VERSION ""

NS_ :

BS_:

BU_: IAP ODS _4WD BCM HUD DATC MDPS AAF_Tester AEMC SMK _4WD EPB CUBIS MTS TMU EVP CGW TPMS LPI DI_BOX SPAS EMS LCA TCU IBOX FATC AFLS FPCM SCC AHLS AVM ABS SNV OPI PGS SAS AAF Dummy LDWS_LKAS LVR ESC PSB CLU ECS ACU REA

BO_ 67 DATC13: 8 DATC
 SG_ CF_Datc_TempDispUnit : 0|2@1+ (1,0) [0|3] "" CLU,IBOX
 SG_ CF_Datc_ModDisp : 2|4@1+ (1,0) [0|15] "" CLU
 SG_ CF_Datc_IonClean : 6|2@1+ (1,0) [0|3] "" CLU
 SG_ CF_Datc_ChgReqDisp : 8|2@1+ (1,0) [0|3] "" CLU
 SG_ CF_Datc_IntakeDisp : 10|2@1+ (1,0) [0|3] "" CLU
 SG_ CF_Datc_AutoDisp : 12|2@1+ (1,0) [0|3] "" CLU
 SG_ CF_Datc_FrDefLed : 14|2@1+ (1,0) [0|3] "" CLU,IBOX
 SG_ CF_Datc_AutoDefogBlink : 16|2@1+ (1,0) [0|3] "" CLU
 SG_ CF_Datc_ClmScanDisp : 18|2@1+ (1,0) [0|3] "" CLU
 SG_ CF_Datc_AqsDisp : 20|2@1+ (1,0) [0|3] "" CLU
 SG_ CF_Datc_AcDisp : 22|2@1+ (1,0) [0|3] "" CLU
 SG_ CF_Datc_OpSts : 25|3@1+ (1,0) [0|7] "" CLU
 SG_ CF_Mtc_MaxAcDisp : 28|2@1+ (1,0) [0|3] "" CLU
 SG_ CF_Datc_DualDisp : 30|2@1+ (1,0) [0|3] "" CLU
 SG_ CF_Datc_PwrInf : 32|4@1+ (1,0) [0|15] "" CLU
 SG_ CF_Datc_RearManual : 38|2@1+ (1,0) [0|3] "" CLU
 SG_ CF_Datc_RearAutoDisp : 40|2@1+ (1,0) [0|1] "" CLU
 SG_ CF_Datc_RearOffDisp : 42|2@1+ (1,0) [0|3] "" CLU
 SG_ CF_Datc_RearClimateScnDisp : 44|2@1+ (1,0) [0|3] "" CLU
 SG_ CF_Datc_RearChgReqDisp : 46|2@1+ (1,0) [0|3] "" CLU
 SG_ CF_Datc_RearModDisp : 48|4@1+ (1,0) [0|15] "" CLU
 SG_ CF_Datc_RearBlwDisp : 52|4@1+ (1,0) [0|15] "" CLU
 SG_ CF_Datc_PSModDisp : 56|4@1+ (1,0) [0|15] "" CLU
 SG_ CF_Datc_FrontBlwDisp : 60|4@1+ (1,0) [0|15] "" CLU,IBOX

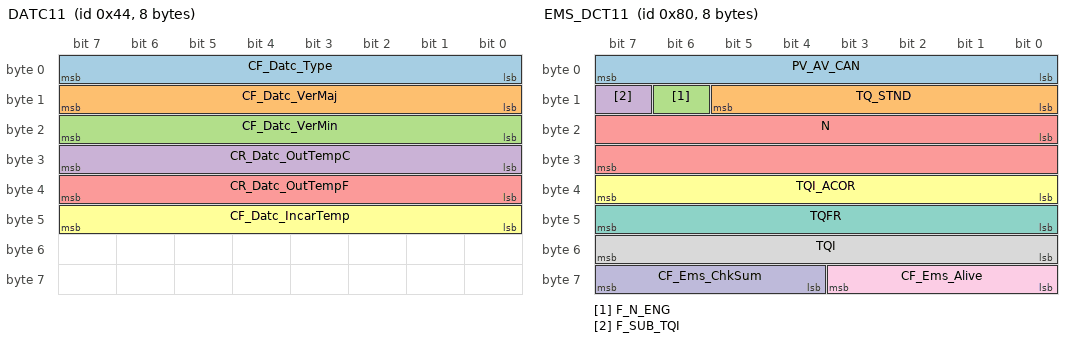
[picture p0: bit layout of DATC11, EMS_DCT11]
BO_ 68 DATC11: 8 DATC
 SG_ CF_Datc_Type : 0|8@1+ (1,0) [0|255] "" CLU
 SG_ CF_Datc_VerMaj : 8|8@1+ (1,0) [0|255] "" CLU
 SG_ CF_Datc_VerMin : 16|8@1+ (1,0) [0|255] "" CLU
 SG_ CR_Datc_OutTempC : 24|8@1+ (0.5,-41) [-41|86.5] "deg" CLU,FPCM
 SG_ CR_Datc_OutTempF : 32|8@1+ (1,-42) [-42|213] "deg" CLU
 SG_ CF_Datc_IncarTemp : 40|8@1+ (0.5,-40) [-40|60] "deg" BCM,CLU

BO_ 128 EMS_DCT11: 8 EMS
 SG_ PV_AV_CAN : 0|8@1+ (0.3906,0) [0|99.603] "%" TCU
 SG_ TQ_STND : 8|6@1+ (10,0) [0|630] "Nm" TCU
 SG_ F_N_ENG : 14|1@1+ (1,0) [0|1] "" TCU
 SG_ F_SUB_TQI : 15|1@1+ (1,0) [0|1] "" TCU
 SG_ N : 16|16@1+ (0.25,0) [0|16383.75] "rpm" TCU
 SG_ TQI_ACOR : 32|8@1+ (0.390625,0) [0|99.6094] "%" IBOX,TCU
 SG_ TQFR : 40|8@1+ (0.390625,0) [0|99.6094] "%" TCU
 SG_ TQI : 48|8@1+ (0.390625,0) [0|99.609375] "%" TCU
 SG_ CF_Ems_Alive : 56|4@1+ (1,0) [0|15] "" TCU
 SG_ CF_Ems_ChkSum : 60|4@1+ (1,0) [0|15] "" TCU

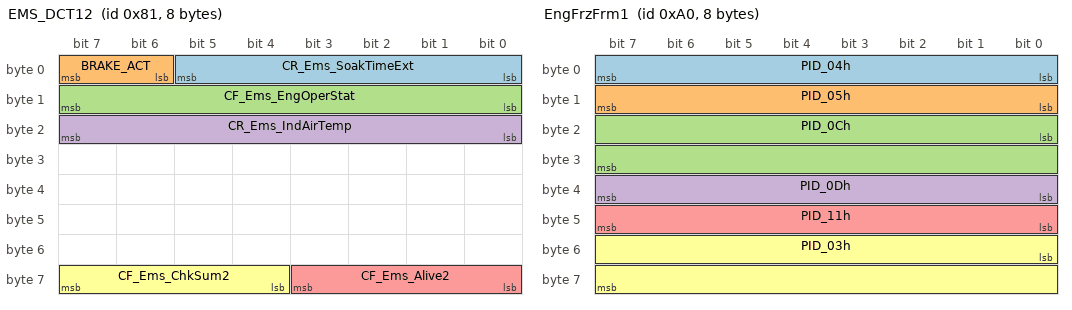
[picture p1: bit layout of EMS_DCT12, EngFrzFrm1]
BO_ 129 EMS_DCT12: 8 EMS
 SG_ CR_Ems_SoakTimeExt : 0|6@1+ (5,0) [0|315] "Min" TCU
 SG_ BRAKE_ACT : 6|2@1+ (1,0) [0|3] "" TCU
 SG_ CF_Ems_EngOperStat : 8|8@1+ (1,0) [0|255] "" TCU
 SG_ CR_Ems_IndAirTemp : 16|8@1+ (0.75,-48) [-48|143.25] "deg" TCU
 SG_ CF_Ems_Alive2 : 56|4@1+ (1,0) [0|15] "" TCU
 SG_ CF_Ems_ChkSum2 : 60|4@1+ (1,0) [0|15] "" TCU

BO_ 160 EngFrzFrm1: 8 XXX
 SG_ PID_04h : 0|8@1+ (0.392157,0) [0|100] "%" XXX
 SG_ PID_05h : 8|8@1+ (1,-40) [-40|215] "" XXX
 SG_ PID_0Ch : 16|16@1+ (0.25,0) [0|16383.8] "rpm" XXX
 SG_ PID_0Dh : 32|8@1+ (1,0) [0|255] "km/h" XXX
 SG_ PID_11h : 40|8@1+ (0.392157,0) [0|100] "%" XXX
 SG_ PID_03h : 48|16@1+ (1,0) [0|65535] "" XXX

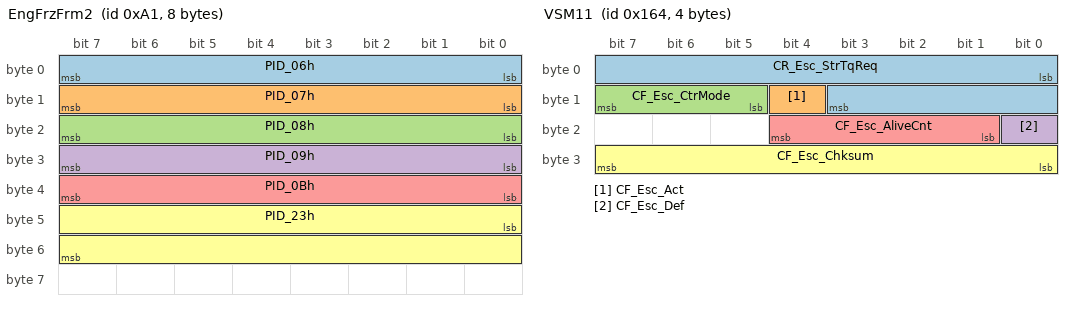
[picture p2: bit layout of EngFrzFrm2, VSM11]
BO_ 161 EngFrzFrm2: 8 XXX
 SG_ PID_06h : 0|8@1+ (0.78125,-100) [-100|99.22] "%" XXX
 SG_ PID_07h : 8|8@1+ (0.78125,-100) [-100|99.22] "%" XXX
 SG_ PID_08h : 16|8@1+ (0.78125,-100) [-100|99.22] "%" XXX
 SG_ PID_09h : 24|8@1+ (0.78125,-100) [-100|99.22] "%" XXX
 SG_ PID_0Bh : 32|8@1+ (1,0) [0|255] "kPa" XXX
 SG_ PID_23h : 40|16@1+ (10,0) [0|655350] "kPa" XXX

BO_ 339 TCS11: 8 ESC
 SG_ TCS_REQ : 0|1@1+ (1,0) [0|1] "" _4WD,EMS,EPB,TCU
 SG_ MSR_C_REQ : 1|1@1+ (1,0) [0|1] "" EMS,EPB,SCC,TCU
 SG_ TCS_PAS : 2|1@1+ (1,0) [0|1] "" _4WD,CLU,EMS,SCC,SPAS,TCU
 SG_ TCS_GSC : 3|1@1+ (1,0) [0|1] "" _4WD,EMS,TCU
 SG_ CF_Esc_LimoInfo : 4|2@1+ (1,0) [0|3] "" _4WD,SCC
 SG_ ABS_DIAG : 6|1@1+ (1,0) [0|1] "" _4WD,CLU,EMS,EPB
 SG_ ABS_DEF : 7|1@1+ (1,0) [0|1] "" _4WD,ACU,ECS,EMS,EPB,SCC,SPAS,TCU
 SG_ TCS_DEF : 8|1@1+ (1,0) [0|1] "" _4WD,EMS,EPB,SCC,SPAS,TCU
 SG_ TCS_CTL : 9|1@1+ (1,0) [0|1] "" _4WD,EMS,EPB,SCC,SPAS,TCU
 SG_ ABS_ACT : 10|1@1+ (1,0) [0|1] "" _4WD,ACU,ECS,EMS,EPB,LDWS_LKAS,SCC,SPAS,TCU
 SG_ EBD_DEF : 11|1@1+ (1,0) [0|1] "" _4WD,EMS,EPB,SPAS,TCU
 SG_ ESP_PAS : 12|1@1+ (1,0) [0|1] "" _4WD,ACU,CLU,EMS,EPB,LDWS_LKAS,SCC,TCU
 SG_ ESP_DEF : 13|1@1+ (1,0) [0|1] "" _4WD,ACU,ECS,EMS,EPB,LDWS_LKAS,SCC,TCU
 SG_ ESP_CTL : 14|1@1+ (1,0) [0|1] "" _4WD,ACU,ECS,EMS,EPB,LDWS_LKAS,SCC,SPAS,TCU
 SG_ TCS_MFRN : 15|1@1+ (1,0) [0|1] "" EMS,EPB,TCU
 SG_ DBC_CTL : 16|1@1+ (1,0) [0|1] "" _4WD,EMS,EPB
 SG_ DBC_PAS : 17|1@1+ (1,0) [0|1] "" _4WD,EMS,EPB
 SG_ DBC_DEF : 18|1@1+ (1,0) [0|1] "" _4WD,EMS,EPB
 SG_ HAC_CTL : 19|1@1+ (1,0) [0|1] "" _4WD,CLU,EMS,EPB,TCU
 SG_ HAC_PAS : 20|1@1+ (1,0) [0|1] "" _4WD,CLU,EMS,EPB,TCU
 SG_ HAC_DEF : 21|1@1+ (1,0) [0|1] "" _4WD,CLU,EMS,EPB,TCU
 SG_ ESS_STAT : 22|2@1+ (1,0) [0|3] "" _4WD,BCM,CLU,EMS,EPB
 SG_ TQI_TCS : 24|8@1+ (0.390625,0) [0|99.609375] "%" EMS,EPB,TCU
 SG_ TQI_MSR : 32|8@1+ (0.390625,0) [0|99.609375] "%" EMS,EPB,TCU
 SG_ TQI_SLW_TCS : 40|8@1+ (0.390625,0) [0|99.609375] "%" EMS,EPB,TCU
 SG_ CF_Esc_BrkCtl : 48|1@1+ (1,0) [0|1] "" EMS
 SG_ BLA_CTL : 49|2@1+ (1,0) [0|3] "" BCM,CGW,CLU
 SG_ AliveCounter_TCS1 : 52|4@1+ (1,0) [0|14] "" EMS,EPB,LDWS_LKAS
 SG_ CheckSum_TCS1 : 56|8@1+ (1,0) [0|255] "" EMS,EPB,LDWS_LKAS

BO_ 356 VSM11: 4 ESC
 SG_ CR_Esc_StrTqReq : 0|12@1+ (0.01,-20.48) [-20.48|20.47] "Nm" MDPS
 SG_ CF_Esc_Act : 12|1@1+ (1,0) [0|1] "" LDWS_LKAS,MDPS
 SG_ CF_Esc_CtrMode : 13|3@1+ (1,0) [0|7] "" MDPS
 SG_ CF_Esc_Def : 16|1@1+ (1,0) [0|1] "" MDPS
 SG_ CF_Esc_AliveCnt : 17|4@1+ (1,0) [0|15] "" LDWS_LKAS,MDPS
 SG_ CF_Esc_Chksum : 24|8@1+ (1,0) [0|255] "" LDWS_LKAS,MDPS

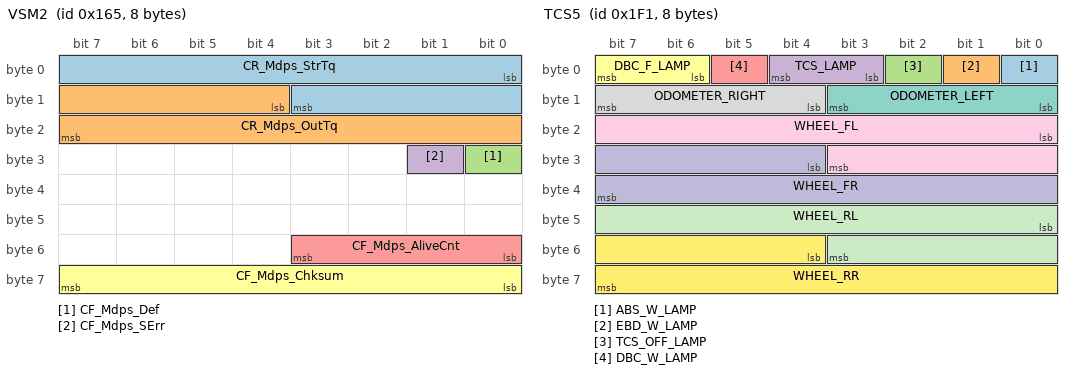
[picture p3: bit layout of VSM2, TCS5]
BO_ 357 VSM2: 8 XXX
 SG_ CR_Mdps_StrTq : 0|12@1+ (0.01,-20.48) [-20.48|20.47] "Nm" XXX
 SG_ CR_Mdps_OutTq : 12|12@1+ (0.1,-204.8) [-204.8|204.7] "" XXX
 SG_ CF_Mdps_Def : 24|1@1+ (1,0) [0|1] "" XXX
 SG_ CF_Mdps_SErr : 25|1@1+ (1,0) [0|1] "" XXX
 SG_ CF_Mdps_AliveCnt : 48|4@1+ (1,0) [0|15] "" XXX
 SG_ CF_Mdps_Chksum : 56|8@1+ (1,0) [0|255] "" XXX

BO_ 399 EMS_H12: 8 EMS
 SG_ R_TqAcnApvC : 0|8@1+ (0.2,0) [0|51] "Nm" DATC,IBOX
 SG_ R_PAcnC : 8|8@1+ (125,0) [0|31875] "hPa" DATC,IBOX
 SG_ TQI_B : 16|8@1+ (0.390625,0) [0|99.609375] "%" ABS,ESC,IBOX
 SG_ SLD_VS : 24|8@1+ (1,0) [0|255] "km/h" CLU,IBOX
 SG_ CF_CdaStat : 32|3@1+ (1,0) [0|7] "" AEMC,IBOX,TCU
 SG_ CF_Ems_IsgStat : 35|3@1+ (1,0) [0|7] "" ABS,BCM,CLU,DATC,EPB,ESC,IBOX,LDWS_LKAS,MDPS,SMK,TCU
 SG_ CF_Ems_OilChg : 38|1@1+ (1,0) [0|1] "" CLU,IBOX
 SG_ CF_Ems_EtcLimpMod : 39|1@1+ (1,0) [0|1] "" CLU,IBOX
 SG_ R_NEngIdlTgC : 40|8@1+ (10,0) [0|2550] "rpm" DATC,IBOX,TCU
 SG_ CF_Ems_UpTarGr : 48|1@1+ (1,0) [0|1] "" CLU,IBOX
 SG_ CF_Ems_DownTarGr : 49|1@1+ (1,0) [0|1] "" CLU,IBOX
 SG_ CF_Ems_DesCurGr : 50|4@1+ (1,0) [0|15] "" CLU,IBOX
 SG_ CF_Ems_SldAct : 54|1@1+ (1,0) [0|1] "" CLU,IBOX
 SG_ CF_Ems_SldPosAct : 55|1@1+ (1,0) [0|1] "" CLU,IBOX
 SG_ CF_Ems_HPresStat : 56|1@1+ (1,0) [0|1] "" IBOX,TCU
 SG_ CF_Ems_IsgBuz : 57|1@1+ (1,0) [0|1] "" CLU,IBOX
 SG_ CF_Ems_IdlStpFCO : 58|1@1+ (1,0) [0|1] "" CLU,IBOX
 SG_ CF_Ems_FCopen : 59|1@1+ (1,0) [0|1] "" CLU,IBOX
 SG_ CF_Ems_ActEcoAct : 60|1@1+ (1,0) [0|1] "" CLU,IBOX,TCU
 SG_ CF_Ems_EngRunNorm : 61|1@1+ (1,0) [0|1] "" ABS,ESC,IBOX,TCU
 SG_ CF_Ems_IsgStat2 : 62|2@1+ (2,0) [0|3] "" CLU,IBOX,TCU

BO_ 497 TCS5: 8 XXX
 SG_ ABS_W_LAMP : 0|1@1+ (1,0) [0|1] "" XXX
 SG_ EBD_W_LAMP : 1|1@1+ (1,0) [0|1] "" XXX
 SG_ TCS_OFF_LAMP : 2|1@1+ (1,0) [0|1] "" XXX
 SG_ TCS_LAMP : 3|2@1+ (1,0) [0|3] "" XXX
 SG_ DBC_W_LAMP : 5|1@1+ (1,0) [0|1] "" XXX
 SG_ DBC_F_LAMP : 6|2@1+ (1,0) [0|3] "" XXX
 SG_ ODOMETER_LEFT : 8|4@1+ (1,0) [0|15] "m" XXX
 SG_ ODOMETER_RIGHT : 12|4@1+ (1,0) [0|15] "m" XXX
 SG_ WHEEL_FL : 16|12@1+ (0.125,0) [0|511.875] "km/h" XXX
 SG_ WHEEL_FR : 28|12@1+ (0.125,0) [0|511.875] "km/h" XXX
 SG_ WHEEL_RL : 40|12@1+ (0.125,0) [0|511.875] "km/h" XXX
 SG_ WHEEL_RR : 52|12@1+ (0.125,0) [0|511.875] "km/h" XXX

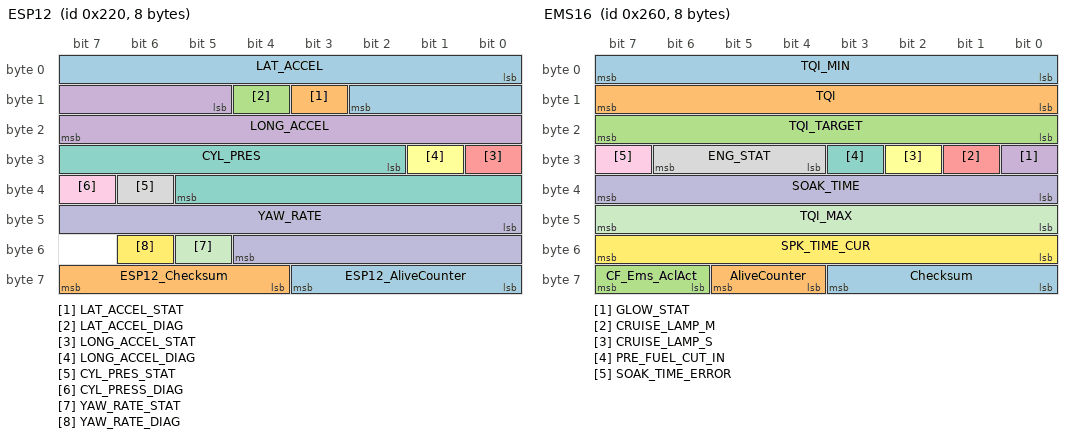
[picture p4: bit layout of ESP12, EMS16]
BO_ 544 ESP12: 8 ESC
 SG_ LAT_ACCEL : 0|11@1+ (0.01,-10.23) [-10.23|10.24] "m/s^2" _4WD,ECS,IBOX,LCA,LDWS_LKAS,MDPS,PSB,SCC,TCU
 SG_ LAT_ACCEL_STAT : 11|1@1+ (1,0) [0|1] "" _4WD,IBOX,LDWS_LKAS,MDPS,PSB,SCC,TCU
 SG_ LAT_ACCEL_DIAG : 12|1@1+ (1,0) [0|1] "" _4WD,IBOX,LDWS_LKAS,MDPS,PSB,SCC,TCU
 SG_ LONG_ACCEL : 13|11@1+ (0.01,-10.23) [-10.23|10.24] "m/s^2" _4WD,ECS,EMS,EPB,IBOX,LCA,LDWS_LKAS,PSB,SCC,SPAS,TCU
 SG_ LONG_ACCEL_STAT : 24|1@1+ (1,0) [0|1] "" _4WD,EMS,EPB,IBOX,LDWS_LKAS,PSB,SCC,SPAS,TCU
 SG_ LONG_ACCEL_DIAG : 25|1@1+ (1,0) [0|1] "" _4WD,EMS,EPB,IBOX,LDWS_LKAS,PSB,SCC,SPAS,TCU
 SG_ CYL_PRES : 26|12@1+ (0.1,0) [0|409.5] "Bar" _4WD,ECS,EMS,EPB,IBOX,LDWS_LKAS,PSB,SCC,TCU
 SG_ CYL_PRES_STAT : 38|1@1+ (1,0) [0|1] "" _4WD,ECS,EMS,EPB,IBOX,LDWS_LKAS,PSB,SCC,TCU
 SG_ CYL_PRESS_DIAG : 39|1@1+ (1,0) [0|1] "" _4WD,ECS,EMS,EPB,IBOX,PSB,SCC,TCU
 SG_ YAW_RATE : 40|13@1+ (0.01,-40.95) [-40.95|40.96] "" _4WD,AFLS,IBOX,LCA,LDWS_LKAS,MDPS,PSB,SCC,SPAS,TCU
 SG_ YAW_RATE_STAT : 53|1@1+ (1,0) [0|1] "" _4WD,AFLS,IBOX,LCA,LDWS_LKAS,MDPS,PSB,SCC,SPAS,TCU
 SG_ YAW_RATE_DIAG : 54|1@1+ (1,0) [0|1] "" _4WD,AFLS,IBOX,LCA,LDWS_LKAS,MDPS,PSB,SCC,SPAS,TCU
 SG_ ESP12_AliveCounter : 56|4@1+ (1,0) [0|15] "" _4WD,EMS,LPI,TCU,TMU
 SG_ ESP12_Checksum : 60|4@1+ (1,0) [0|15] "" _4WD,EMS,LPI,TCU,TMU

BO_ 608 EMS16: 8 EMS
 SG_ TQI_MIN : 0|8@1+ (0.390625,0) [0|99.609375] "%" ESC,IBOX,TCU
 SG_ TQI : 8|8@1+ (0.390625,0) [0|99.609375] "%" ESC,IBOX,TCU
 SG_ TQI_TARGET : 16|8@1+ (0.390625,0) [0|99.609375] "%" EPB,ESC,IBOX,TCU
 SG_ GLOW_STAT : 24|1@1+ (1,0) [0|1] "" BCM,CLU,IBOX,SMK
 SG_ CRUISE_LAMP_M : 25|1@1+ (1,0) [0|1] "" CLU,IBOX,TCU
 SG_ CRUISE_LAMP_S : 26|1@1+ (1,0) [0|1] "" CLU,IBOX,TCU
 SG_ PRE_FUEL_CUT_IN : 27|1@1+ (1,0) [0|1] "" IBOX,TCU
 SG_ ENG_STAT : 28|3@1+ (1,0) [0|7] "" ABS,AHLS,AVM,BCM,CLU,EPB,ESC,EVP,FPCM,IBOX,LCA,LDWS_LKAS,MDPS,SCC,SMK,TCU
 SG_ SOAK_TIME_ERROR : 31|1@1+ (1,0) [0|1] "" DATC,EPB,IBOX,TCU
 SG_ SOAK_TIME : 32|8@1+ (1,0) [0|255] "Min" _4WD,DATC,EPB,IBOX,TCU
 SG_ TQI_MAX : 40|8@1+ (0.390625,0) [0|99.609375] "%" ESC,IBOX,TCU
 SG_ SPK_TIME_CUR : 48|8@1+ (0.375,-35.625) [-35.625|60] "" IBOX,TCU
 SG_ Checksum : 56|4@1+ (1,0) [0|15] "" ECS,IBOX,LDWS_LKAS,MDPS,SCC
 SG_ AliveCounter : 60|2@1+ (1,0) [0|3] "" IBOX,LDWS_LKAS,MDPS,SCC
 SG_ CF_Ems_AclAct : 62|2@1+ (1,0) [0|3] "" IBOX,SCC

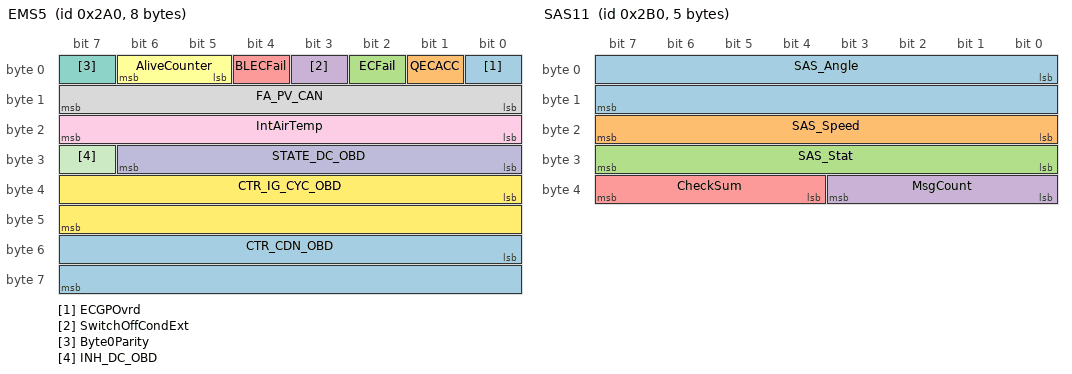
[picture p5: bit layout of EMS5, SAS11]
BO_ 672 EMS5: 8 XXX
 SG_ ECGPOvrd : 0|1@1+ (1,0) [0|1] "" XXX
 SG_ QECACC : 1|1@1+ (1,0) [0|1] "" XXX
 SG_ ECFail : 2|1@1+ (1,0) [0|1] "" XXX
 SG_ SwitchOffCondExt : 3|1@1+ (1,0) [0|1] "" XXX
 SG_ BLECFail : 4|1@1+ (1,0) [0|1] "" XXX
 SG_ AliveCounter : 5|2@1+ (1,0) [0|3] "" XXX
 SG_ Byte0Parity : 7|1@1+ (1,0) [0|1] "" XXX
 SG_ FA_PV_CAN : 8|8@1+ (0.3906,0) [0|99.2] "%" XXX
 SG_ IntAirTemp : 16|8@1+ (0.75,-48) [-48|143.25] "" XXX
 SG_ STATE_DC_OBD : 24|7@1+ (1,0) [0|127] "" XXX
 SG_ INH_DC_OBD : 31|1@1+ (1,0) [0|1] "" XXX
 SG_ CTR_IG_CYC_OBD : 32|16@1+ (1,0) [0|65535] "" XXX
 SG_ CTR_CDN_OBD : 48|16@1+ (1,0) [0|65535] "" XXX

BO_ 688 SAS11: 5 MDPS
 SG_ SAS_Angle : 0|16@1- (0.1,0) [-3276.8|3276.7] "Deg" _4WD,ACU,AFLS,AVM,CLU,ECS,EMS,ESC,IBOX,LCA,LDWS_LKAS,PGS,PSB,SCC,SPAS,TCU,_4WD,ACU,AFLS,AVM,BCM,CLU,ECS,EMS,ESC,IBOX,LCA,LDWS_LKAS,PGS,PSB,SCC,SPAS,TCU
 SG_ SAS_Speed : 16|8@1+ (4,0) [0|1016] "" AFLS,ECS,ESC,IBOX,LDWS_LKAS,SCC,SPAS,TCU,AFLS,ECS,ESC,IBOX,LDWS_LKAS,SCC,SPAS,TCU
 SG_ SAS_Stat : 24|8@1+ (1,0) [0|255] "" ECS,ESC,IBOX,LDWS_LKAS,PSB,SCC,SPAS,TCU,ECS,ESC,IBOX,LDWS_LKAS,PSB,SCC,SPAS,TCU
 SG_ MsgCount : 32|4@1+ (1,0) [0|15] "" ECS,ESC,IBOX,LDWS_LKAS,PSB,SCC,SPAS,ECS,ESC,IBOX,LDWS_LKAS,PSB,SCC,SPAS
 SG_ CheckSum : 36|4@1+ (1,0) [0|15] "" ECS,EMS,ESC,IBOX,LDWS_LKAS,PSB,SCC,SPAS,ECS,EMS,ESC,IBOX,LDWS_LKAS,PSB,SCC,SPAS

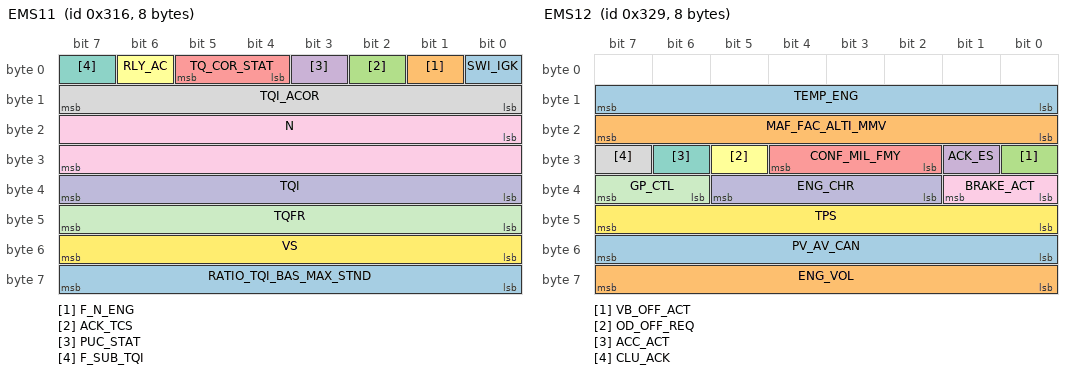
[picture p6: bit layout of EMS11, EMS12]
BO_ 790 EMS11: 8 EMS
 SG_ SWI_IGK : 0|1@1+ (1,0) [0|1] "" _4WD,ABS,ACU,AHLS,CUBIS,DI_BOX,ECS,EPB,ESC,IBOX,LDWS_LKAS,MDPS,REA,SAS,SCC,TCU
 SG_ F_N_ENG : 1|1@1+ (1,0) [0|1] "" _4WD,ACU,AFLS,CLU,CUBIS,DATC,ECS,EPB,ESC,IBOX,MDPS,SCC,TCU
 SG_ ACK_TCS : 2|1@1+ (1,0) [0|1] "" ESC,IBOX
 SG_ PUC_STAT : 3|1@1+ (1,0) [0|1] "" _4WD,CLU,DATC,IBOX,TCU
 SG_ TQ_COR_STAT : 4|2@1+ (1,0) [0|3] "" _4WD,ESC,IBOX,TCU
 SG_ RLY_AC : 6|1@1+ (1,0) [0|1] "" DATC,IBOX,TCU
 SG_ F_SUB_TQI : 7|1@1+ (1,0) [0|1] "" _4WD,ECS,EPB,ESC,IBOX,TCU
 SG_ TQI_ACOR : 8|8@1+ (0.390625,0) [0|99.6094] "%" _4WD,EPB,ESC,IBOX,TCU
 SG_ N : 16|16@1+ (0.25,0) [0|16383.75] "rpm" _4WD,ACU,AFLS,CLU,CUBIS,DATC,ECS,EPB,ESC,FPCM,IBOX,MDPS,SCC,TCU
 SG_ TQI : 32|8@1+ (0.390625,0) [0|99.6094] "%" _4WD,ECS,EPB,ESC,IBOX,TCU
 SG_ TQFR : 40|8@1+ (0.390625,0) [0|99.6094] "%" _4WD,EPB,ESC,IBOX,TCU
 SG_ VS : 48|8@1+ (1,0) [0|254] "km/h" _4WD,AAF,ACU,AHLS,BCM,CLU,DATC,ECS,EPB,IBOX,LCA,LDWS_LKAS,LVR,MDPS,ODS,SCC,SMK,SPAS,TCU,TPMS
 SG_ RATIO_TQI_BAS_MAX_STND : 56|8@1+ (0.0078,0) [0|2] "" _4WD,IBOX,TCU

BO_ 809 EMS12: 8 EMS
 SG_ TEMP_ENG : 8|8@1+ (0.75,-48) [-48|143.25] "deg" _4WD,BCM,CLU,DATC,EPB,ESC,IBOX,SMK,TCU
 SG_ MAF_FAC_ALTI_MMV : 16|8@1+ (0.00781,0) [0|1.99155] "" IBOX,TCU
 SG_ VB_OFF_ACT : 24|1@1+ (1,0) [0|1] "" IBOX,TCU
 SG_ ACK_ES : 25|1@1+ (1,0) [0|1] "" _4WD,ACU,IBOX
 SG_ CONF_MIL_FMY : 26|3@1+ (1,0) [0|7] "" ESC,IBOX,TCU
 SG_ OD_OFF_REQ : 29|1@1+ (1,0) [0|1] "" IBOX,TCU
 SG_ ACC_ACT : 30|1@1+ (1,0) [0|1] "" _4WD,ABS,CLU,ESC,IAP,IBOX,SCC,TCU
 SG_ CLU_ACK : 31|1@1+ (1,0) [0|1] "" _4WD,EPB,ESC,IBOX
 SG_ BRAKE_ACT : 32|2@1+ (1,0) [0|3] "" _4WD,ABS,ACU,AFLS,CLU,DATC,ECS,EPB,ESC,IBOX,LDWS_LKAS,TCU
 SG_ ENG_CHR : 34|4@1+ (1,0) [0|15] "" _4WD,ABS,ACU,CLU,DATC,EPB,ESC,FATC,IBOX,SCC,SMK,TCU
 SG_ GP_CTL : 38|2@1+ (1,0) [0|3] "" IBOX
 SG_ TPS : 40|8@1+ (0.4694836,-15.0234742) [-15.0234742|104.6948357] "%" _4WD,ABS,ACU,CLU,DATC,ECS,EPB,ESC,IBOX,TCU
 SG_ PV_AV_CAN : 48|8@1+ (0.3906,0) [0|99.603] "%" _4WD,AAF,ABS,ACU,AFLS,CLU,DATC,EPB,ESC,IAP,IBOX,LDWS_LKAS,SCC,TCU
 SG_ ENG_VOL : 56|8@1+ (0.1,0) [0|25.5] "liter" _4WD,ABS,ACU,BCM,CLU,DATC,EPB,ESC,IBOX,LDWS_LKAS,SCC,SMK

BO_ 880 TCU3: 8 XXX
 SG_ N_TGT_LUP : 0|8@1+ (10,500) [500|3040] "rpm" XXX
 SG_ SLOPE_TCU : 8|6@1+ (0.5,-16) [-16|15.5] "%" XXX
 SG_ CF_Tcu_InhCda : 14|1@1+ (1,0) [0|1] "" XXX
 SG_ CF_Tcu_IsgInhib : 15|1@1+ (1,0) [0|1] "" XXX
 SG_ CF_Tcu_BkeOnReq : 16|2@1+ (1,0) [0|3] "" XXX
 SG_ CF_Tcu_NCStat : 18|2@1+ (1,0) [0|3] "" XXX
 SG_ CF_Tcu_TarGr : 20|4@1+ (1,0) [0|15] "" XXX
 SG_ CF_Tcu_ShfPatt : 24|4@1+ (1,0) [0|15] "" XXX
 SG_ CF_Tcu_InhVis : 28|1@1+ (1,0) [0|1] "" XXX
 SG_ CF_Tcu_PRelReq : 29|1@1+ (1,0) [0|1] "" XXX
 SG_ CF_Tcu_ITPhase : 30|1@1+ (1,0) [0|1] "" XXX
 SG_ CF_Tcu_ActEcoRdy : 31|1@1+ (1,0) [0|1] "" XXX
 SG_ CF_Tcu_TqGrdLim : 32|8@1+ (10,0) [0|2540] "Nm/s" XXX
 SG_ CR_Tcu_IsgTgtRPM : 40|8@1+ (20,0) [0|3500] "rpm" XXX
 SG_ TQI_TCU_INC : 48|8@1+ (0.390625,0) [0|99.6094] "%" XXX
 SG_ CF_Tcu_SbwPInfo : 56|1@1+ (1,0) [0|1] "" XXX
 SG_ CF_Tcu_SptRdy : 57|1@1+ (1,0) [0|1] "" XXX
 SG_ CF_Tcu_Alive3 : 58|2@1+ (1,0) [0|3] "" XXX
 SG_ CF_Tcu_ChkSum3 : 60|4@1+ (1,0) [0|15] "" XXX

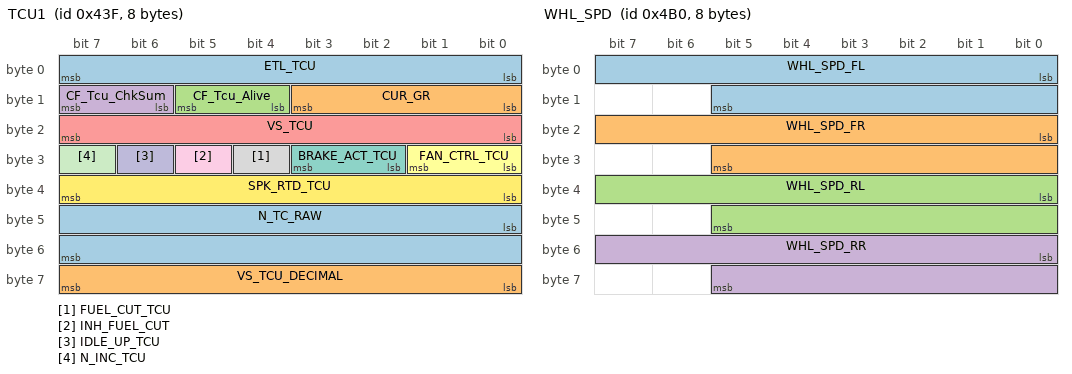
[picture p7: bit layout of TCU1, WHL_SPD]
BO_ 1087 TCU1: 8 XXX
 SG_ ETL_TCU : 0|8@1+ (2,0) [0|508] "Nm" XXX
 SG_ CUR_GR : 8|4@1+ (1,0) [0|15] "" XXX
 SG_ CF_Tcu_Alive : 12|2@1+ (1,0) [0|3] "" XXX
 SG_ CF_Tcu_ChkSum : 14|2@1+ (1,0) [0|3] "" XXX
 SG_ VS_TCU : 16|8@1+ (1,0) [0|254] "km/h" XXX
 SG_ FAN_CTRL_TCU : 24|2@1+ (1,0) [0|3] "" XXX
 SG_ BRAKE_ACT_TCU : 26|2@1+ (1,0) [0|3] "" XXX
 SG_ FUEL_CUT_TCU : 28|1@1+ (1,0) [0|1] "" XXX
 SG_ INH_FUEL_CUT : 29|1@1+ (1,0) [0|1] "" XXX
 SG_ IDLE_UP_TCU : 30|1@1+ (1,0) [0|1] "" XXX
 SG_ N_INC_TCU : 31|1@1+ (1,0) [0|1] "" XXX
 SG_ SPK_RTD_TCU : 32|8@1+ (0.375,-23.625) [-15|15] "" XXX
 SG_ N_TC_RAW : 40|16@1+ (0.25,0) [0|16383.5] "rpm" XXX
 SG_ VS_TCU_DECIMAL : 56|8@1+ (0.0078125,0) [0|0.992188] "km/h" XXX

BO_ 1200 WHL_SPD: 8 XXX
 SG_ WHL_SPD_FL : 0|14@1+ (0.03125,0) [0|511.969] "km/h" XXX
 SG_ WHL_SPD_FR : 16|14@1+ (0.03125,0) [0|511.969] "km/h" XXX
 SG_ WHL_SPD_RL : 32|14@1+ (0.03125,0) [0|511.969] "km/h" XXX
 SG_ WHL_SPD_RR : 48|14@1+ (0.03125,0) [0|511.969] "km/h" XXX

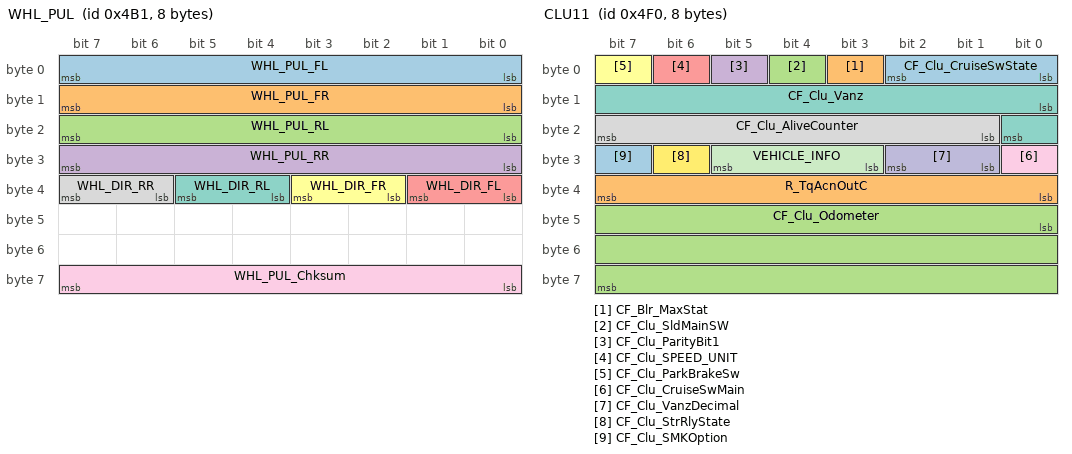
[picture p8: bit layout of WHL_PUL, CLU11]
BO_ 1201 WHL_PUL: 8 XXX
 SG_ WHL_PUL_FL : 0|8@1+ (0.5,0) [0|127.5] "pulse count" XXX
 SG_ WHL_PUL_FR : 8|8@1+ (0.5,0) [0|127.5] "pulse count" XXX
 SG_ WHL_PUL_RL : 16|8@1+ (0.5,0) [0|127.5] "pulse count" XXX
 SG_ WHL_PUL_RR : 24|8@1+ (0.5,0) [0|127.5] "pulse count" XXX
 SG_ WHL_DIR_FL : 32|2@1+ (1,0) [0|3] "" XXX
 SG_ WHL_DIR_FR : 34|2@1+ (1,0) [0|3] "" XXX
 SG_ WHL_DIR_RL : 36|2@1+ (1,0) [0|3] "" XXX
 SG_ WHL_DIR_RR : 38|2@1+ (1,0) [0|3] "" XXX
 SG_ WHL_PUL_Chksum : 56|8@1+ (1,0) [0|255] "" XXX

BO_ 1264 CLU11: 8 XXX
 SG_ CF_Clu_CruiseSwState : 0|3@1+ (1,0) [0|7] "" XXX
 SG_ CF_Blr_MaxStat : 3|1@1+ (1,0) [0|1] "" XXX
 SG_ CF_Clu_SldMainSW : 4|1@1+ (1,0) [0|1] "" XXX
 SG_ CF_Clu_ParityBit1 : 5|1@1+ (1,0) [0|1] "pulse count" XXX
 SG_ CF_Clu_SPEED_UNIT : 6|1@1+ (1,0) [0|1] "" XXX
 SG_ CF_Clu_ParkBrakeSw : 7|1@1+ (1,0) [0|1] "" XXX
 SG_ CF_Clu_Vanz : 8|9@1+ (0.5,0) [0|255.5] "km/h or MPH" XXX
 SG_ CF_Clu_AliveCounter : 17|7@1+ (1,0) [0|127] "" XXX
 SG_ CF_Clu_CruiseSwMain : 24|1@1+ (1,0) [0|1] "" XXX
 SG_ CF_Clu_VanzDecimal : 25|2@1+ (1,0) [0|0.375] "" XXX
 SG_ VEHICLE_INFO : 27|3@1+ (1,0) [0|7] "" XXX
 SG_ CF_Clu_StrRlyState : 30|1@1+ (1,0) [0|1] "" XXX
 SG_ CF_Clu_SMKOption : 31|1@1+ (1,0) [0|1] "" XXX
 SG_ R_TqAcnOutC : 32|8@1+ (1,0) [0|51] "Nm" XXX
 SG_ CF_Clu_Odometer : 40|24@1+ (0.1,0) [0|1677720] "km" XXX

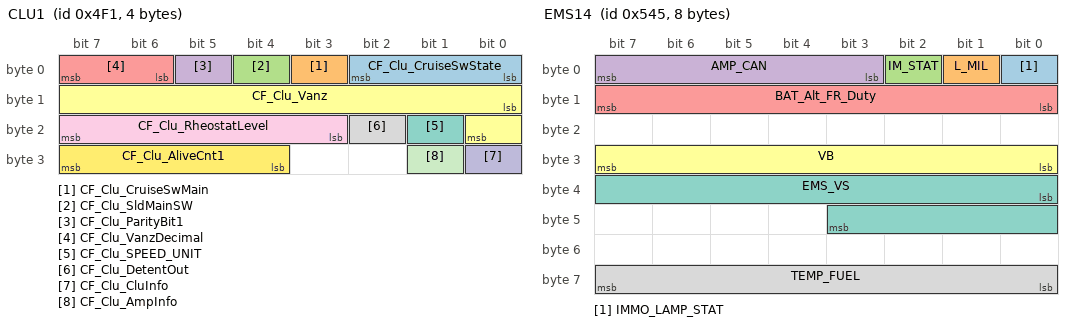
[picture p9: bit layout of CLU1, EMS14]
BO_ 1265 CLU1: 4 CLU
 SG_ CF_Clu_CruiseSwState : 0|3@1+ (1,0) [0|7] "" EMS,LDWS_LKAS,SCC
 SG_ CF_Clu_CruiseSwMain : 3|1@1+ (1,0) [0|1] "" EMS,LDWS_LKAS,SCC
 SG_ CF_Clu_SldMainSW : 4|1@1+ (1,0) [0|1] "" EMS
 SG_ CF_Clu_ParityBit1 : 5|1@1+ (1,0) [0|1] "pulse count" EMS
 SG_ CF_Clu_VanzDecimal : 6|2@1+ (0.125,0) [0|0.375] "" EMS
 SG_ CF_Clu_Vanz : 8|9@1+ (0.5,0) [0|255.5] "km/h or MPH" BCM,CUBIS,EMS,IBOX,LDWS_LKAS,MDPS,SCC
 SG_ CF_Clu_SPEED_UNIT : 17|1@1+ (1,0) [0|1] "" BCM,CUBIS,EMS,IBOX,LDWS_LKAS,MDPS,SCC
 SG_ CF_Clu_DetentOut : 18|1@1+ (1,0) [0|1] "" AVM,BCM,LCA,PGS,SPAS
 SG_ CF_Clu_RheostatLevel : 19|5@1+ (1,0) [0|31] "" AVM,BCM,LCA,PGS,SPAS
 SG_ CF_Clu_CluInfo : 24|1@1+ (1,0) [0|1] "" BCM
 SG_ CF_Clu_AmpInfo : 25|1@1+ (1,0) [0|1] "" BCM
 SG_ CF_Clu_AliveCnt1 : 28|4@1+ (1,0) [0|15] "" AHLS,EMS,EPB,LDWS_LKAS,MDPS,SCC

BO_ 1349 EMS14: 8 EMS
 SG_ IMMO_LAMP_STAT : 0|1@1+ (1,0) [0|1] "" CLU,IBOX
 SG_ L_MIL : 1|1@1+ (1,0) [0|1] "" CLU,CUBIS,IBOX
 SG_ IM_STAT : 2|1@1+ (1,0) [0|1] "" CLU,IBOX
 SG_ AMP_CAN : 3|5@1+ (10.731613,458.98) [458.98|791.660003] "mmHg" CLU,IBOX,TCU,TPMS
 SG_ BAT_Alt_FR_Duty : 8|8@1+ (0.4,0) [0|100] "%" CGW,CUBIS,IBOX,TMU
 SG_ VB : 24|8@1+ (0.1015625,0) [0|25.8984375] "V" CLU,CUBIS,DATC,EPB,FPCM,IBOX
 SG_ EMS_VS : 32|12@1+ (0.0625,0) [0|255.875] "km/h" CLU
 SG_ TEMP_FUEL : 56|8@1+ (0.75,-48) [-48|143.25] "deg" FPCM

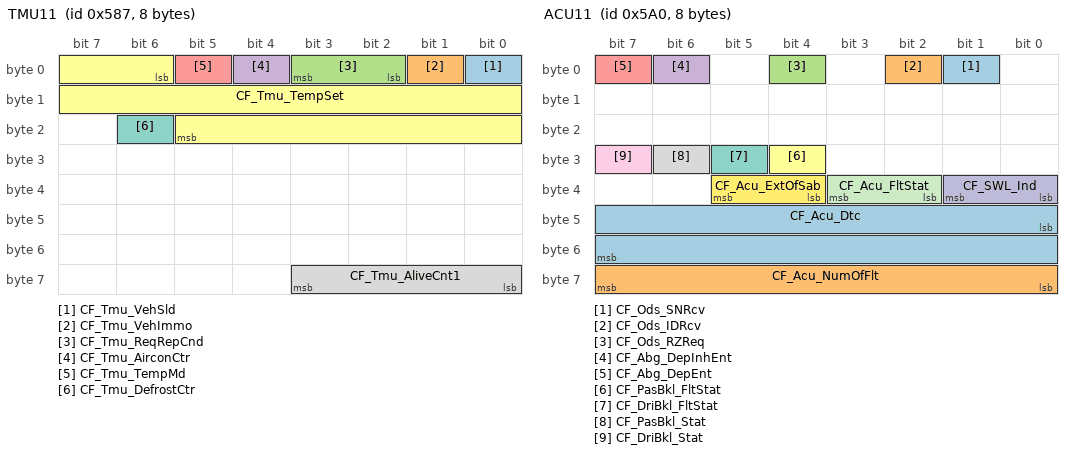
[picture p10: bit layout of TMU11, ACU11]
BO_ 1415 TMU11: 8 IBOX
 SG_ CF_Tmu_VehSld : 0|1@1+ (1,0) [0|1] "" EMS
 SG_ CF_Tmu_VehImmo : 1|1@1+ (1,0) [0|1] "" EMS
 SG_ CF_Tmu_ReqRepCnd : 2|2@1+ (1,0) [0|3] "" EMS
 SG_ CF_Tmu_AirconCtr : 4|1@1+ (1,0) [0|1] "" DATC
 SG_ CF_Tmu_TempMd : 5|1@1+ (1,0) [0|1] "" DATC
 SG_ CF_Tmu_TempSet : 6|16@1+ (1,0) [0|20] "" DATC
 SG_ CF_Tmu_DefrostCtr : 22|1@1+ (1,0) [0|1] "" DATC,FATC
 SG_ CF_Tmu_AliveCnt1 : 56|4@1+ (1,0) [0|15] "" EMS

BO_ 1440 ACU11: 8 ACU
 SG_ CF_Ods_SNRcv : 1|1@1+ (1,0) [0|1] "" ODS
 SG_ CF_Ods_IDRcv : 2|1@1+ (1,0) [0|1] "" ODS
 SG_ CF_Ods_RZReq : 4|1@1+ (1,0) [0|1] "" ODS
 SG_ CF_Abg_DepInhEnt : 6|1@1+ (1,0) [0|1] "" ODS
 SG_ CF_Abg_DepEnt : 7|1@1+ (1,0) [0|1] "" ODS
 SG_ CF_PasBkl_FltStat : 28|1@1+ (1,0) [0|1] "" ODS,PSB
 SG_ CF_DriBkl_FltStat : 29|1@1+ (1,0) [0|1] "" ODS,PSB
 SG_ CF_PasBkl_Stat : 30|1@1+ (1,0) [0|1] "" IBOX,ODS,PSB,TMU
 SG_ CF_DriBkl_Stat : 31|1@1+ (1,0) [0|1] "" ODS,PSB
 SG_ CF_SWL_Ind : 32|2@1+ (1,0) [0|3] "" CUBIS,IBOX
 SG_ CF_Acu_FltStat : 34|2@1+ (1,0) [0|3] "" CUBIS,IBOX
 SG_ CF_Acu_ExtOfSab : 36|2@1+ (1,0) [0|3] "" BCM,CLU,CUBIS,IBOX
 SG_ CF_Acu_Dtc : 40|16@1+ (1,0) [0|65535] "" CUBIS,IBOX
 SG_ CF_Acu_NumOfFlt : 56|8@1+ (1,0) [0|255] "" CUBIS,IBOX

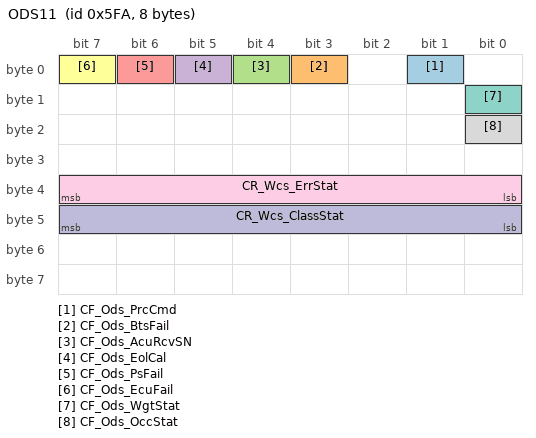
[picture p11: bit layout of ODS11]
BO_ 1530 ODS11: 8 ODS
 SG_ CF_Ods_PrcCmd : 1|1@1+ (1,0) [0|1] "" Dummy
 SG_ CF_Ods_BtsFail : 3|1@1+ (1,0) [0|1] "" Dummy
 SG_ CF_Ods_AcuRcvSN : 4|1@1+ (1,0) [0|1] "" ACU
 SG_ CF_Ods_EolCal : 5|1@1+ (1,0) [0|1] "" ACU
 SG_ CF_Ods_PsFail : 6|1@1+ (1,0) [0|1] "" ACU
 SG_ CF_Ods_EcuFail : 7|1@1+ (1,0) [0|1] "" ACU
 SG_ CF_Ods_WgtStat : 8|1@1+ (1,0) [0|1] "" ACU
 SG_ CF_Ods_OccStat : 16|1@1+ (1,0) [0|1] "" ACU
 SG_ CR_Wcs_ErrStat : 32|8@1+ (1,0) [0|63] "" ACU
 SG_ CR_Wcs_ClassStat : 40|8@1+ (1,0) [0|4] "" ACU,BCM

BO_ 1680 CLU2: 8 XXX
 SG_ CF_Clu_IGNSw : 0|3@1+ (1,0) [0|7] "" XXX
 SG_ RKE_CMD : 3|3@1+ (1,0) [0|7] "" XXX
 SG_ CF_Clu_DrvDrSw : 6|2@1+ (1,0) [0|3] "" XXX
 SG_ CF_Clu_DrvKeyLockSw : 8|1@1+ (1,0) [0|1] "" XXX
 SG_ CF_Clu_DrvKeyUnlockSw : 9|1@1+ (1,0) [0|1] "" XXX
 SG_ PIC_Lock : 10|3@1+ (1,0) [0|7] "" XXX
 SG_ PIC_Unlock : 13|3@1+ (1,0) [0|7] "" XXX
 SG_ CF_Clu_DrvSeatBeltSw : 16|2@1+ (1,0) [0|3] "" XXX
 SG_ CF_Clu_TrunkTgSw : 18|2@1+ (1,0) [0|3] "" XXX
 SG_ CF_Clu_AstSeatBeltSw : 20|2@1+ (1,0) [0|3] "" XXX
 SG_ CF_Clu_HoodSw : 22|2@1+ (1,0) [0|3] "" XXX
 SG_ CF_Clu_TurnSigLh : 24|1@1+ (1,0) [0|1] "" XXX
 SG_ CF_Clu_TurnSigRh : 25|1@1+ (1,0) [0|1] "" XXX
 SG_ CF_Clu_LdwsLkasSW : 26|1@1+ (1,0) [0|1] "" XXX
 SG_ CF_Clu_WiperIntT : 27|3@1+ (1,0) [0|7] "" XXX
 SG_ CF_Clu_WiperIntSW : 30|1@1+ (1,0) [0|1] "" XXX
 SG_ CF_Clu_WiperLow : 31|1@1+ (1,0) [0|1] "" XXX
 SG_ CF_Clu_WiperHigh : 32|1@1+ (1,0) [0|1] "" XXX
 SG_ CF_Clu_WiperAuto : 33|1@1+ (1,0) [0|1] "" XXX
 SG_ CF_Clu_RainSnsStat : 34|3@1+ (1,0) [0|7] "" XXX
 SG_ CF_Clu_HeadLampLow : 37|1@1+ (1,0) [0|1] "" XXX
 SG_ CF_Clu_HeadLampHigh : 38|1@1+ (1,0) [0|1] "" XXX
 SG_ CF_Clu_AltLStatus : 39|1@1+ (1,0) [0|1] "" XXX
 SG_ CF_Clu_EcoDriveInf : 40|3@1+ (1,0) [0|7] "" XXX
 SG_ CF_Clu_SwiGearR : 43|2@1+ (1,0) [0|3] "" XXX
 SG_ CF_Clu_SWL_Stat : 45|3@1+ (1,0) [0|7] "" XXX
 SG_ CF_Clu_ActiveEcoSW : 48|1@1+ (1,0) [0|1] "" XXX
 SG_ CF_Clu_HazardSW : 49|1@1+ (1,0) [0|1] "" XXX
 SG_ CF_Clu_AliveCnt2 : 50|4@1+ (1,0) [0|15] "" XXX
 SG_ CF_Clu_AstDrSw : 54|2@1+ (1,0) [0|3] "" XXX
 SG_ CF_Clu_LkasDispMode : 56|2@1+ (1,0) [0|3] "" XXX
 SG_ CF_Clu_AutoLightLevel : 58|2@1+ (1,0) [0|3] "" XXX
 SG_ CF_Clu_SunRoofOpenState : 60|1@1+ (1,0) [0|1] "" XXX
